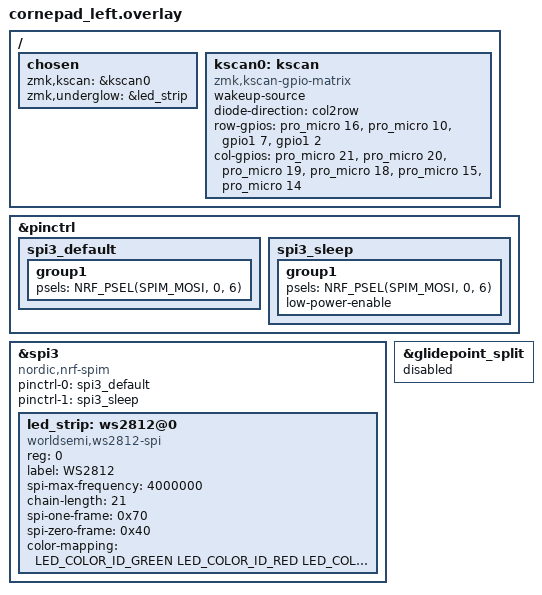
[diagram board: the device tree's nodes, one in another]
#include "cornepad.dtsi"

#include <dt-bindings/led/led.h>

// LED
&pinctrl {
    spi3_default: spi3_default {
        group1 {
            psels = <NRF_PSEL(SPIM_MOSI, 0, 6)>;
        };
    };

    spi3_sleep: spi3_sleep {
        group1 {
            psels = <NRF_PSEL(SPIM_MOSI, 0, 6)>;
            low-power-enable;
        };
    };
};

&spi3 {
  compatible = "nordic,nrf-spim";
  status = "okay";

  pinctrl-0 = <&spi3_default>;
  pinctrl-1 = <&spi3_sleep>;
  pinctrl-names = "default", "sleep";

  led_strip: ws2812@0 {
    compatible = "worldsemi,ws2812-spi";
    reg = <0>;
    label = "WS2812";
    spi-max-frequency = <4000000>;

    chain-length = <21>;
    spi-one-frame = <0x70>;
    spi-zero-frame = <0x40>;
    color-mapping = <LED_COLOR_ID_GREEN
                     LED_COLOR_ID_RED
                     LED_COLOR_ID_BLUE>;
  };
};

/ {
    chosen {
        zmk,kscan = &kscan0;
        zmk,underglow = &led_strip;
    };

    kscan0: kscan {
        compatible = "zmk,kscan-gpio-matrix";
        wakeup-source;
        diode-direction = "col2row";
        row-gpios
            = <&pro_micro 16 (GPIO_ACTIVE_HIGH | GPIO_PULL_DOWN)>
            , <&pro_micro 10 (GPIO_ACTIVE_HIGH | GPIO_PULL_DOWN)>
            , <&gpio1 7 (GPIO_ACTIVE_HIGH | GPIO_PULL_DOWN)>
            , <&gpio1 2 (GPIO_ACTIVE_HIGH | GPIO_PULL_DOWN)>
            ;

        col-gpios
            = <&pro_micro 21 GPIO_ACTIVE_HIGH>
            , <&pro_micro 20 GPIO_ACTIVE_HIGH>
            , <&pro_micro 19 GPIO_ACTIVE_HIGH>
            , <&pro_micro 18 GPIO_ACTIVE_HIGH>
            , <&pro_micro 15 GPIO_ACTIVE_HIGH>
            , <&pro_micro 14 GPIO_ACTIVE_HIGH>
            ;

    };
};


&glidepoint_split {
    status= "disabled";
};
